# TOP_RCM_TOP_RCM register map
Vendor: Texas Instruments
Peripheral module from a debugger description file (folder AM263).
Registers are 32-bit, read-write, reset 0x0 unless marked. A register's access mark holds for its fields unless they carry their own. Offsets are as the file gives them; lines under a group give offsets from that group; [hi:lo] are bit positions; {n}, {i} and the like mark numbered series; 'fields as' and 'values as' point back to an identical list; <NAME> marks a mode.

## TOP_RCM_TOP_RCM
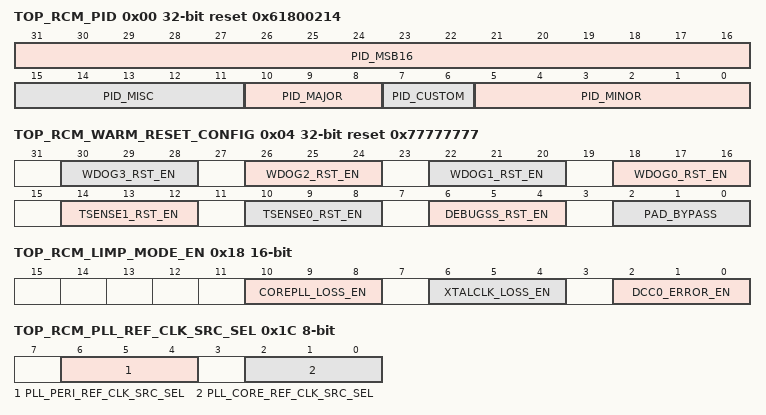
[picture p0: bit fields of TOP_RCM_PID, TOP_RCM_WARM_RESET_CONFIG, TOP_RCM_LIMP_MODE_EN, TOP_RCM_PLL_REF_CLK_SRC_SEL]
0x00 TOP_RCM_PID ro reset 0x61800214
  [31:16] PID_MSB16 — Not Defined
  [15:11] PID_MISC — Not Defined
  [10:8] PID_MAJOR — Not Defined
  [7:6] PID_CUSTOM — Not Defined
  [5:0] PID_MINOR — Not Defined
0x04 TOP_RCM_WARM_RESET_CONFIG reset 0x77777777
  [4n+18:4n+16] WDOG{n}_RST_EN (n=0..3) — Data should be loaded as multibit. Write 3'b000 to disable corresponding Watchdog control on Warm reset Write 3'b111 enable corresponding Watchdog to control Warm reset
  [14:12] TSENSE1_RST_EN — Data should be loaded as multibit. Write 3'b000 to disable temperature sensor 1 on Warm reset Write 3'b111 to enable temperature sensor 1l on Warm reset
  [10:8] TSENSE0_RST_EN — Data should be loaded as multibit. Write 3'b000 to disable temperature sensor 0 control on Warm reset Write 3'b111 to enable temperature sensor 0 control on Warm reset
  [6:4] DEBUGSS_RST_EN — Data should be loaded as multibit. Write 3'b000 to disable debugger control on Warm reset Write 3'b111 enable debugger to control Warm reset
  [2:0] PAD_BYPASS — Bypass the Warm reset from Pad InputData should be loaded as multibit. Write 3'b000 : Pad Warm Reset pin has control over warm resetWrite 3'b111 : Pad warm reset pin has no control on warm reset
0x08 TOP_RCM_WARM_RESET_REQ 8-bit reset 0x7
  [2:0] SW_RST — Data should be loaded as multibit. Write 3'b000 to assert warm reset from SWWrite 3'b111 to deassert warm reset from SW if this is the only source of warm reset
0x0C TOP_RCM_WARM_RST_CAUSE 16-bit ro reset 0x41
  [11:0] CAUSE — System Reset Cause register12'b0000_0100_0001 - POR reset12'b0000_0100_0010 - Warm reset due to MSS_WDT012'b0000_0100_0100 - Warm reset due to MSS_WDT112'b0000_0100_1000 - Warm reset due to MSS_WDT212'b0000_0101_0000 - Warm reset due to MSS_WDT312'b0000_0110_0000 - Warm reset due to TOP_RMC:WARM_RESET_REQ12'b0000_0100_0000 - External Pad reset12'b0000_1100_0000 - Warm reset due to HSM_WDT12'b0001_0100_0000 - Warm Reset due to Deugger reset12'b0010_0100_0000 - Warm Reset due to Temp Sense0 Reset12'b0100_0100_0000 - Warm Reset due to Temp Sense1 Reset
0x10 TOP_RCM_WARM_RST_CAUSE_CLR 8-bit
  [2:0] CLEAR — Write pulse bit field: Data should be loaded as multibit. System Reset Cause register Clear
0x14 TOP_RCM_RCOSC32K_CTRL 8-bit
  [2:0] STOPOSC — Stop 32KHz RCOSC. Write 3'b111 to stop clock
0x18 TOP_RCM_LIMP_MODE_EN 16-bit
  [10:8] COREPLL_LOSS_EN — Enable for core pll phase lock loss to generate Limp mode3'b000: will not generate Limp mode (multibit 000)3'b111 : will generate Limp mode (multibit 111)
  [6:4] XTALCLK_LOSS_EN — Enable for crystal_clock_loss to generate Limp mode3'b000: will not generate Limp mode (multibit 000)3'b111 : will generate Limp mode (multibit 111)
  [2:0] DCC0_ERROR_EN — Enable DCC0 Error to generate Limp mode 3'b000: DCC0 Error will not generate Limp mode (multibit 000)3'b111 : DCC0 Error will generate Limp mode (multibit 111)
0x1C TOP_RCM_PLL_REF_CLK_SRC_SEL 8-bit
  [6:4] PLL_PERI_REF_CLK_SRC_SEL — Mux selct for PERI PLL REF clockWrite 3'b111 : to select external reference clock as PLL reference clockWrite 3'b000 : to select on-die clock as PLL reference clock
  [2:0] PLL_CORE_REF_CLK_SRC_SEL — Mux selct for CORE PLL REF clockWrite 3'b111 : to select external reference clock as PLL reference clockWrite 3'b000 : to select on-die clock as PLL reference clock
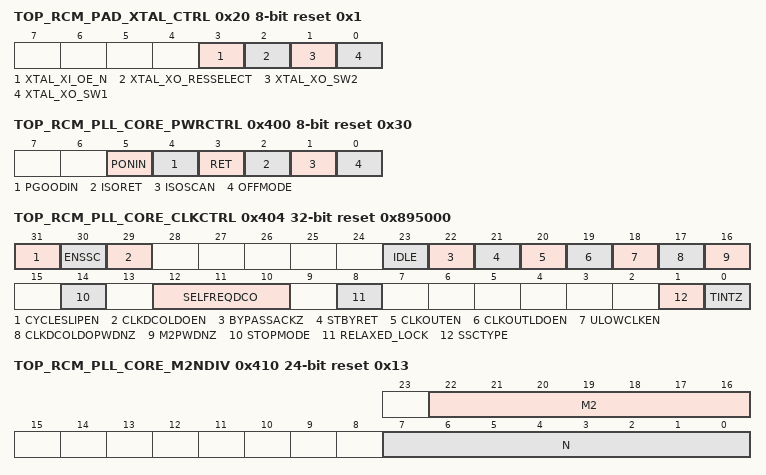
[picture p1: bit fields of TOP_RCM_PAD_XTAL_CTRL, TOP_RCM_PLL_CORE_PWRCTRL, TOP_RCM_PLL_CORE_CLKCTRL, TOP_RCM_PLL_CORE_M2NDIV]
0x20 TOP_RCM_PAD_XTAL_CTRL 8-bit reset 0x1
  [3] XTAL_XI_OE_N — When gz is low, the padxo output is enabled, padxi to padxo is a single stage inverter, and the oscillator can oscillate with an external crystal plus capacitors/resistor. When gz is high, padxo is in high impedance mode, padxi and Y are driven low, and the oscillator is disabled. With gz high, the internal bias resistor between padxi and padxo is disconnected regardless of the state of resselect.
  [2] XTAL_XO_RESSELECT — When resselect is low, an internal 1Meg Ohm resistor is connected between padxi and padxo for oscillator bias. When resselect is asserted (high), the internal resistor is disconnected. For oscillation with a crystal while resselect is high, an external resistor must be connected between padxi and padxo to provide bias.
  [1] XTAL_XO_SW2 — XTAL pad control bit frequency selection pin SW2 Based on table belowsw2 sw1 Freq of operation0 0 5 20 MHz0 1 15 35 MHz1 0 30 40 MHz1 1 40 55 MHz
  [0] XTAL_XO_SW1 — XTAL pad control bit frequency selection pin SW1 Based on table belowsw2 sw1 Freq of operation0 0 5 20 MHz0 1 15 35 MHz1 0 30 40 MHz1 1 40 55 MHz
0x24 TOP_RCM_SOP_MODE_VALUE ro
  [31:0] VAL — See below table SOP_MODE values and its corresponding mappingSOP_PAD3 SOP_PAD2 SOP_PAD1 SOP_PAD0 bootmode 0 0 0 0 QSPI Functional mode(4S) 0 0 0 1 UART Functional mode 0 0 1 0 QSPI Functional mode(1S) values from 3 to 7 is reserved for future use 1 0 0 0 THB(test) mode 1 0 0 1 ATPG mode 1 0 1 0 FLED mode (Debug SoP mode) values from B to F is reserved for future use reset value of MMR is 0 but it will latch on to the SOP mode values after reset is released. when CPU reads the MMR it will show the latched SOP mode value only
0x28 TOP_RCM_CLK_LOSS_STATUS 8-bit ro reset 0x100
  [8] RC_GOOD_BOOT — Clock status of RC clock at boot. Reset value will reflect the actual status1 --> clock present at boot0 --> clock not present at boot
  [4] RC_CLOCK_LOSS — Coarse detection clock loss status for RC clock. Reset value will reflect the actual status1 --> clock lost0 --> clock good
  [0] CRYSTAL_CLOCK_LOSS — Coarse detection clock loss status for Crystal clock. Reset value will reflect the actual status1 --> clock lost0 --> clock good
0x30 TOP_RCM_WARM_RSTTIME1 16-bit reset 0x888
  [11:0] DELAY — programing Output delay Data should be loaded as multibit. For example: if value of 0x5 should be selected then 0x555 should be configured to the register.
0x34 TOP_RCM_WARM_RSTTIME2 16-bit reset 0x888
  [11:0] DELAY — programing input Rise delay Data should be loaded as multibit. For example: if value of 0x5 should be selected then 0x555 should be configured to the register.
0x38 TOP_RCM_WARM_RSTTIME3 16-bit reset 0x111
  [11:0] DELAY — programing Input Fall delay Data should be loaded as multibit. For example: if value of 0x5 should be selected then 0x555 should be configured to the register.
0x400 TOP_RCM_PLL_CORE_PWRCTRL 8-bit reset 0x30
  [5] PONIN — ON/OFF control of the weak power switch digital. For functionalmode it should be 1
  [4] PGOODIN — ON/OFF control of the strong power switch digital. For functional mode it should be 1
  [3] RET — Save/Restore control for Retention mode. For functional mode itshould be 0
  [2] ISORET — Save/Restore control for Isolation of output pins For functional modeit should be 0
  [1] ISOSCAN — Save/Restore control for Isolation of the Scanout pins. For functionalmode it should be 0
  [0] OFFMODE — Used to switch OFF the logic on VDDA. For functional mode itshould be 0
0x404 TOP_RCM_PLL_CORE_CLKCTRL reset 0x895000
  [31] CYCLESLIPEN — FailSafe enable to trigger re-calibration in case CycleSlip occurs between REFCLK and FBCLK.
  [30] ENSSC — Controls Clock Spreading. SSC is not supported. Should be set to 0x0 to disable clock spreading.
  [29] CLKDCOLDOEN — Synchronously enables/disables CLKDCOLDO0x0 : synchronously disables CLKDCOLDO0x1 : synchronously enables CLKDCOLDO
  [23] IDLE — Sets PLL to Idle mode0x0 : When SYSRESET = 0 and TINITZ = 1 IDLE = 0 PLL will go toActive and Locked0x1 : When SYSRESET = 0 and TINITZ = 1 IDLE = 1 PLL will go toIdle Bypass low powe
  [22] BYPASSACKZ — BYPASSACKZ is a special purpose input to the module. In generalthis input is expected to be tied to static low. For the output clocks ofthe module that do not have an internal bypass mux viz.CLKDCOLDO and CLKOUTLDO, a bypass mux could beimplemented external to the module.
  [21] STBYRET — Standby retention control0x0 : prepares ADPLLLJ for relock when out of retention byremoving the gating on all internal clocks.0x1 : prepares ADPLLLJ for retention by gating all the internalclocks.
  [20] CLKOUTEN — CLKOUT enable or disable0x0 : synchronously disables CLKOUT0x1 : synchronously enables CLKOUT
  [19] CLKOUTLDOEN — Synchronously enables/disables CLKOUTLDO 0x0 : synchronously disables CLKOUTLDO 0x1 : synchronously enables CLKOUTLDO
  [18] ULOWCLKEN — Select CLKOUT source in bypass0x0: When ADPLLLJ in bypass mode, CLKOUT = CLKINP/(N2+1)0x1: When ADPLLLJ in bypass mode, CLKOUT = CLKINPULOW.
  [17] CLKDCOLDOPWDNZ — 0 Asynchronous power down for CLKDCOLDO o/p.
  [16] M2PWDNZ — M2 divider power down mode0x0: Asynchronous power down for M2 divider0x1 : M2 divider is functional
  [14] STOPMODE — When in Lossclk/Stbyret 0x0 : Limp mode 0x1 : Stopmode
  [12:10] SELFREQDCO — DCO Clock (DCOCLK = CLKINP * [M/(N+1)]) frequency rangeselector.0x0: Reserved0x2: HS2 : DCOCLK range is from 500 MHz to 1000 MHz0x3: Reserved0x4: HS1: DCOCLK range is from 1000 MHz to 2000 MHz0x5: Reserved
  [8] RELAXED_LOCK — Decides when FREQLOCK asserted0x0: FREQLOCK asserted when DC frequency error less than 1%0x1: FREQLOCK asserted when DC frequency error less than 2%
  [1] SSCTYPE
  [0] TINTZ — PLL core soft reset
0x408 TOP_RCM_PLL_CORE_TENABLE size not given
  [0] TENABLE — M, N. SD and SELFREQDCO latch (active rise edge)
0x40C TOP_RCM_PLL_CORE_TENABLEDIV size not given
  [0] TENABLEDIV — M2 and N2 latch (active rise edge)
0x410 TOP_RCM_PLL_CORE_M2NDIV 24-bit reset 0x13
  [22:16] M2 — Post-divider is REGM2
  [7:0] N — Pre-divider is REGN+1
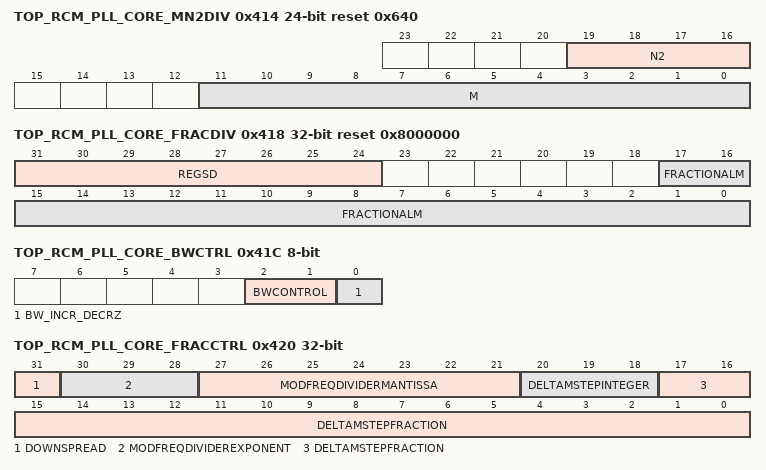
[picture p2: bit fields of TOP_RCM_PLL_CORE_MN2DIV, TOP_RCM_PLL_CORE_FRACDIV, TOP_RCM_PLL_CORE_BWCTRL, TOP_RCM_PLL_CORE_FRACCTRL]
0x414 TOP_RCM_PLL_CORE_MN2DIV 24-bit reset 0x640
  [19:16] N2 — Bypass divider is REGN2+1
  [11:0] M — Feedback Multiplier is REGM
0x418 TOP_RCM_PLL_CORE_FRACDIV reset 0x8000000
  [31:24] REGSD — Sigma-Delta DividerShould be set by s/w to provide optimum jitter performance.DPLL_SD_DIV = CEILING ([DPLL_MULT/(DPLL_DIV+1)] * CLKINP/ 250), where CLKINP is the input clock of the DPLL in MHz
  [17:0] FRACTIONALM — Fractional part of the M divider.
0x41C TOP_RCM_PLL_CORE_BWCTRL 8-bit
  [2:1] BWCONTROL — Change Loop Bandwidth
  [0] BW_INCR_DECRZ — Direction of Loop Bandwidth0x0 : decrease BW0x1 : increase BW
0x420 TOP_RCM_PLL_CORE_FRACCTRL
  [31] DOWNSPREAD — Controls frequency spread0x0 : enables both side frequency spread about the programmed frequency.0x1 : enables low frequency spread only
  [30:28] MODFREQDIVIDEREXPONENT — Exponent of the REFCLK divider to define the modulation frequency.
  [27:21] MODFREQDIVIDERMANTISSA — Mantissa of the REFCLK divider to define the modulation frequency
  [20:18] DELTAMSTEPINTEGER — Integer part of Frequency Spread control
  [17:0] DELTAMSTEPFRACTION — The fraction part of Frequency Spread control
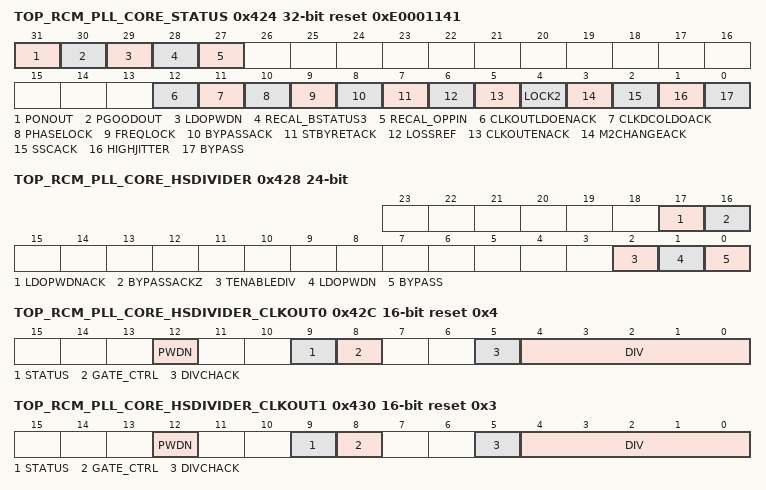
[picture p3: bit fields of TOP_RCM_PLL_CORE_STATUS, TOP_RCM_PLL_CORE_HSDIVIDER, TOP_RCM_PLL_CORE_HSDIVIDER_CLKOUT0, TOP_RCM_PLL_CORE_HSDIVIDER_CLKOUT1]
0x424 TOP_RCM_PLL_CORE_STATUS ro reset 0xE0001141
  [31] PONOUT — Status of the weak power-switch0x0 : indicates the/OFF status of the weak power-switch in digital toSOC.0x1 : ndicates the ON status of the weak power-switch in digital toSOC.
  [30] PGOODOUT — Status of the strong power-switch0x0 : indicates the/OFF status of the strong power-switch in digital toSOC.0x1 : ndicates the ON status of the strong power-switch in digital toSOC.
  [29] LDOPWDN — 1 indicates ADPLLLJ internal LDO is power down. VDDLDOOUT willbe un-defined in this condition
  [28] RECAL_BSTATUS3 — Recalibration status flag. 1 ADPLLLJ requires recalibration
  [27] RECAL_OPPIN — Recalibration status flag. 1 ADPLLLJ requires recalibration
  [12] CLKOUTLDOENACK — Indicates the enable/disable condition of CLKOUTLDOEN0x0 = CLKOUTLDO gating completed0x1 = CLKOUTLDO enabling completed
  [11] CLKDCOLDOACK — Indicates the enable/disable condition of CLKDCOLDOEN0x0 = CLKDCOLDO gating completed0x1 = CLKDCOLOD enabling completed
  [10] PHASELOCK — Status on PHASELOCK output pin
  [9] FREQLOCK — Status on FREQLOCK output pin
  [8] BYPASSACK — Status of BYPASSACK output pin
  [7] STBYRETACK — Standby and retention status0x0: indicates to SOC that all internal clocks in ADPLLLJ are activeand it is starting the relock process.0x1: indicates to SOC that all internal clocks in ADPLLLJ are gatedand it is ready for retention.
  [6] LOSSREF — Reference input loss
  [5] CLKOUTENACK — Indicates the enable/disable condition of CLKOUTEN0x0 = CLKOUT gating completed0x1 = CLKOUT enabling completed
  [4] LOCK2 — ADPLL internal loop lock status
  [3] M2CHANGEACK — Acknowledge for change to M2 divider. Toggles from 1-0 or 0-1(depending on current value) once CLKOUT frequency change hascompleted.
  [2] SSCACK — Spread Spectrum status0x0 : Spread-spectrum Clocking is disabled on output clocks0x1 : Spread-spectrum Clocking is enabled on output clocks
  [1] HIGHJITTER — 1 indicates jitter. After PHASELOCK is asserted high, theHIGHJITTER flag is asserted high if phase error between REFCLKand FBCLK greater than 24%.
  [0] BYPASS — Bypass status signal. 1 CLKOUT in bypass
0x428 TOP_RCM_PLL_CORE_HSDIVIDER 24-bit access per field
  [17] LDOPWDNACK ro — LDO Power Down Ack
  [16] BYPASSACKZ ro — HSDIVIDER Bypass Ack
  [2] TENABLEDIV rw
  [1] LDOPWDN rw — LDO Power Down
  [0] BYPASS rw — HSDIVIDER Bypass
0x42C TOP_RCM_PLL_CORE_HSDIVIDER_CLKOUT0 16-bit access per field reset 0x4
  [12] PWDN rw — Power down for HSDIVIDER M4 divider and hence CLKOUT0 output0h (R/W) = CLKOUT0 divider active1h (R/W) = CLKOUT0 divider is powered down
  [9] STATUS ro — HSDIVIDER CLKOUT0 status0h (R) = The clock output is gated1h (R) = The clock output is enabled
  [8] GATE_CTRL rw — Control gating of HSDIVIDER CLKOUT00h (R/W) = Automatically gate this clock when there is nodependency for it1h (R/W) = Force this clock to stay enabled even if there is norequest
  [5] DIVCHACK ro — Toggle on this status bit after changing HSDIVIDER_CLKOUT0_DIVindicates that the change in divider value has taken effect
  [4:0] DIV rw — DPLL post-divider factor, M4, for internal clock generation.Divide values from 1 to 31.0h (R/W) = Reserved
0x430 TOP_RCM_PLL_CORE_HSDIVIDER_CLKOUT1 16-bit access per field reset 0x3
  [12] PWDN rw — Power down for HSDIVIDER M5 divider and hence CLKOUT1 output0h (R/W) = CLKOUT1 divider active1h (R/W) = CLKOUT1 divider is powered down
  [9] STATUS ro — HSDIVIDER CLKOUT1 status0h (R) = The clock output is gated1h (R) = The clock output is enabled
  [8] GATE_CTRL rw — Control gating of HSDIVIDER CLKOUT10h (R/W) = Automatically gate this clock when there is nodependency for it1h (R/W) = Force this clock to stay enabled even if there is norequest
  [5] DIVCHACK ro — Toggle on this status bit after changing HSDIVIDER_CLKOUT1_DIVindicates that the change in divider value has taken effect
  [4:0] DIV rw — DPLL post-divider factor, M5, for internal clock generation.Divide values from 1 to 31.0h (R/W) = Reserved
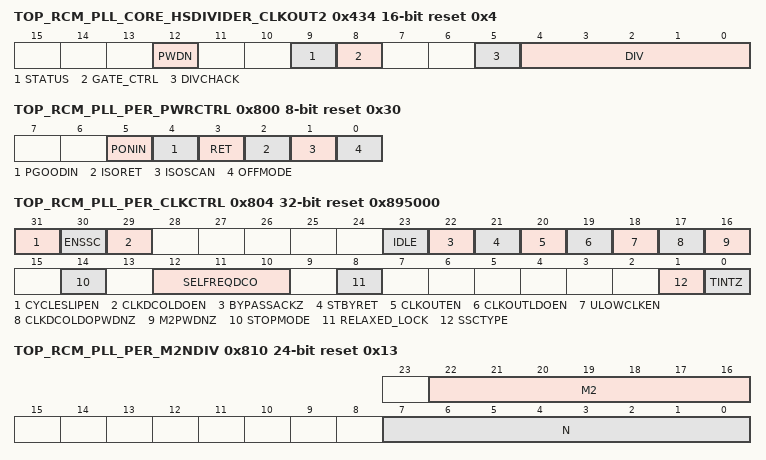
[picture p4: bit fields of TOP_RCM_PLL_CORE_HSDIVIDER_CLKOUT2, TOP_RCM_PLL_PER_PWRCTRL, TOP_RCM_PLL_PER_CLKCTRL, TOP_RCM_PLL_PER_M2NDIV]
0x434 TOP_RCM_PLL_CORE_HSDIVIDER_CLKOUT2 16-bit access per field reset 0x4
  [12] PWDN rw — Power down for HSDIVIDER M6 divider and hence CLKOUT2 output0h (R/W) = CLKOUT2 divider active1h (R/W) = CLKOUT2 divider is powered down
  [9] STATUS ro — HSDIVIDER CLKOUT2 status0h (R) = The clock output is gated1h (R) = The clock output is enabled
  [8] GATE_CTRL rw — Control gating of HSDIVIDER CLKOUT20h (R/W) = Automatically gate this clock when there is nodependency for it1h (R/W) = Force this clock to stay enabled even if there is norequest
  [5] DIVCHACK ro — Toggle on this status bit after changing HSDIVIDER_CLKOUT2_DIVindicates that the change in divider value has taken effect
  [4:0] DIV rw — DPLL post-divider factor, M6, for internal clock generation.Divide values from 1 to 31.0h (R/W) = Reserved
0x43C TOP_RCM_PLL_CORE_RSTCTRL 8-bit
  [2:0] ASSERT — SW Reset override for the PLLWrite 3'b111 : Override is enabled and Reset is asserted
0x440 TOP_RCM_PLL_CORE_HSDIVIDER_RSTCTRL 8-bit
  [2:0] ASSERT — SW Reset override for the HSDIVIDERWrite 3'b111 : Override is enabled and Reset is asserted
0x500 TOP_RCM_R5SS_CLK_SRC_SEL 16-bit
  [11:0] CLKSRCSEL — Select line for selecting source clock for MSS Coretex R5 and System bus Clock.Data should be loaded as multibit. For example: if Clock source 0x5 should be selected then 0x555 should be configured to the register.Refer to AM602 clock spec for source clock reference
0x504 TOP_RCM_R5SS_CLK_STATUS 8-bit ro reset 0x1
  [7:0] CLKINUSE — Status shows the source clock slected for Root clock for CortexR5 and Sysclk
0x510 TOP_RCM_R5SS0_CLK_DIV_SEL 8-bit
  [2:0] CLKDIVSEL — writing 3'b000 Sets R5 clock = R5SS Root clockWriting 3'b111 Sets R5 Clock = SYSCLK
0x514 TOP_RCM_R5SS1_CLK_DIV_SEL 8-bit
  fields as TOP_RCM_R5SS0_CLK_DIV_SEL
0x518 TOP_RCM_R5SS0_CLK_GATE 8-bit
  [2:0] GATED — Only for debug- Functionality not guaranteed Clock gating config for MSS Coretex R5.Data should be loaded as multibit. Write 3'b000 : Clock is ungated (multibit 000)Write 3'b111 : Clock is gated (multibit 111)
0x51C TOP_RCM_R5SS1_CLK_GATE 8-bit
  fields as TOP_RCM_R5SS0_CLK_GATE
0x520 TOP_RCM_SYS_CLK_DIV_VAL 16-bit
  [11:0] CLKDIV — Divider value for System Clock selected clock.Data should be loaded as multibit. For example: if divider value of 0x5 should be selected then 0x555 should be configured to the register.
0x524 TOP_RCM_SYS_CLK_GATE 8-bit
  [2:0] GATED — Only for debug- Functionality not guaranteed Clock gating config for System ClockData should be loaded as multibit. Write 3'b000 : Clock is ungated (multibit 000)Write 3'b111 : Clock is gated (multibit 111)
0x528 TOP_RCM_SYS_CLK_STATUS 16-bit ro
  [15:8] CURRDIVIDER — Status shows the current divider value choosen for Sys Clock
0x800 TOP_RCM_PLL_PER_PWRCTRL 8-bit reset 0x30
  fields as TOP_RCM_PLL_CORE_PWRCTRL
0x804 TOP_RCM_PLL_PER_CLKCTRL reset 0x895000
  fields as TOP_RCM_PLL_CORE_CLKCTRL
0x808 TOP_RCM_PLL_PER_TENABLE size not given
  [0] TENABLE — M, N. SD and SELFREQDCO latch (active rise edge)
0x80C TOP_RCM_PLL_PER_TENABLEDIV size not given
  [0] TENABLEDIV — M2 and N2 latch (active rise edge)
0x810 TOP_RCM_PLL_PER_M2NDIV 24-bit reset 0x13
  [22:16] M2 — Post-divider is REGM2
  [7:0] N — Pre-divider is REGN+1
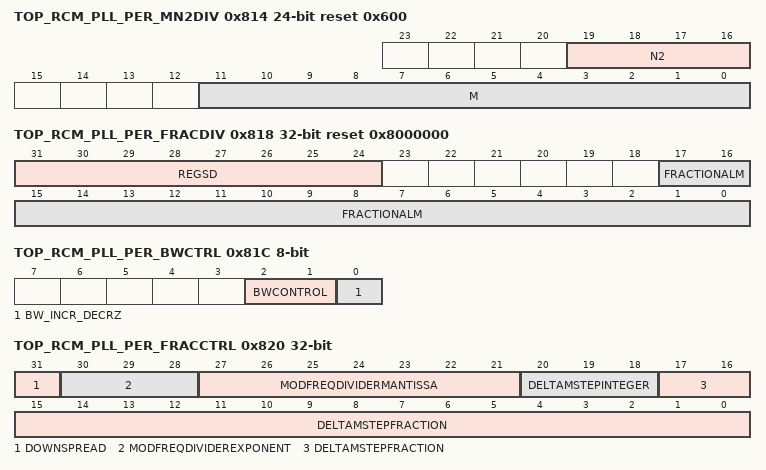
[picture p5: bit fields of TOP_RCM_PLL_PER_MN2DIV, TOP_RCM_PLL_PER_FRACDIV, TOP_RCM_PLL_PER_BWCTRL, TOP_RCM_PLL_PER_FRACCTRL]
0x814 TOP_RCM_PLL_PER_MN2DIV 24-bit reset 0x600
  fields as TOP_RCM_PLL_CORE_MN2DIV
0x818 TOP_RCM_PLL_PER_FRACDIV reset 0x8000000
  fields as TOP_RCM_PLL_CORE_FRACDIV
0x81C TOP_RCM_PLL_PER_BWCTRL 8-bit
  fields as TOP_RCM_PLL_CORE_BWCTRL
0x820 TOP_RCM_PLL_PER_FRACCTRL
  fields as TOP_RCM_PLL_CORE_FRACCTRL
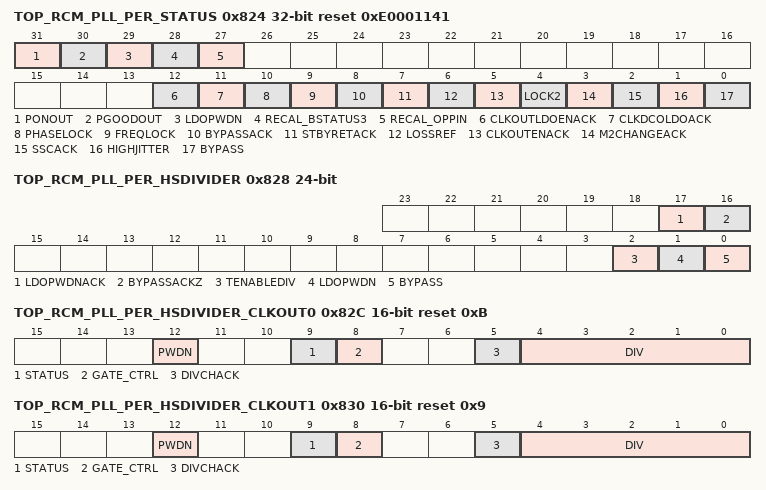
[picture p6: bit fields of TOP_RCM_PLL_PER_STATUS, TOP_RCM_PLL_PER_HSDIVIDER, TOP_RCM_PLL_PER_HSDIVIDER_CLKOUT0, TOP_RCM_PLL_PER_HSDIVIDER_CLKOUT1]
0x824 TOP_RCM_PLL_PER_STATUS ro reset 0xE0001141
  [31] PONOUT — Status of the weak power-switch0x0 : indicates the/OFF status of the weak power-switch in digital toSOC.0x1 : ndicates the ON status of the weak power-switch in digital toSOC.
  [30] PGOODOUT — Status of the strong power-switch0x0 : indicates the/OFF status of the strong power-switch in digital toSOC.0x1 : ndicates the ON status of the strong power-switch in digital toSOC.
  [29] LDOPWDN — 1 indicates ADPLLLJ internal LDO is power down. VDDLDOOUT willbe un-defined in this condition
  [28] RECAL_BSTATUS3 — Recalibration status flag. 1 ADPLLLJ requires recalibration
  [27] RECAL_OPPIN — Recalibration status flag. 1 ADPLLLJ requires recalibration
  [12] CLKOUTLDOENACK — Indicates the enable/disable condition of CLKOUTLDOEN0x0 = CLKOUTLDO gating completed0x1 = CLKOUTLDO enabling completed
  [11] CLKDCOLDOACK — Indicates the enable/disable condition of CLKDCOLDOEN0x0 = CLKDCOLDO gating completed0x1 = CLKDCOLDO enabling completed
  [10] PHASELOCK — Status on PHASELOCK output pin
  [9] FREQLOCK — Status on FREQLOCK output pin
  [8] BYPASSACK — Status of BYPASSACK output pin
  [7] STBYRETACK — Standby and retention status0x0: indicates to SOC that all internal clocks in ADPLLLJ are activeand it is starting the relock process.0x1: indicates to SOC that all internal clocks in ADPLLLJ are gatedand it is ready for retention.
  [6] LOSSREF — Reference input loss
  [5] CLKOUTENACK — Indicates the enable/disable condition of CLKOUTEN0x0 = CLKOUT gating completed0x1 = CLKOUT enabling completed
  [4] LOCK2 — ADPLL internal loop lock status
  [3] M2CHANGEACK — Acknowledge for change to M2 divider. Toggles from 1-0 or 0-1(depending on current value) once CLKOUT frequency change hascompleted.
  [2] SSCACK — Spread Spectrum status0x0 : Spread-spectrum Clocking is disabled on output clocks0x1 : Spread-spectrum Clocking is enabled on output clocks
  [1] HIGHJITTER — 1 indicates jitter. After PHASELOCK is asserted high, theHIGHJITTER flag is asserted high if phase error between REFCLKand FBCLK greater than 24%.
  [0] BYPASS — Bypass status signal. 1 CLKOUT in bypass
0x828 TOP_RCM_PLL_PER_HSDIVIDER 24-bit access per field
  fields as TOP_RCM_PLL_CORE_HSDIVIDER
0x82C TOP_RCM_PLL_PER_HSDIVIDER_CLKOUT0 16-bit access per field reset 0xB
  fields as TOP_RCM_PLL_CORE_HSDIVIDER_CLKOUT0
0x830 TOP_RCM_PLL_PER_HSDIVIDER_CLKOUT1 16-bit access per field reset 0x9
  fields as TOP_RCM_PLL_CORE_HSDIVIDER_CLKOUT1
0x83C TOP_RCM_PLL_PER_RSTCTRL 8-bit
  fields as TOP_RCM_PLL_CORE_RSTCTRL
0x840 TOP_RCM_PLL_PER_HSDIVIDER_RSTCTRL 8-bit
  fields as TOP_RCM_PLL_CORE_HSDIVIDER_RSTCTRL
0xC00 TOP_RCM_CLKOUT0_CLK_SRC_SEL 16-bit
  [11:0] CLKSRCSEL — Select line for selecting source clock for MSS CLKOUT .Data should be loaded as multibit. For example: if Clock source 0x5 should be selected then 0x555 should be configured to the register.Refer to AM602 clock spec for source clock reference
0xC04 TOP_RCM_CLKOUT1_CLK_SRC_SEL 16-bit
  fields as TOP_RCM_CLKOUT0_CLK_SRC_SEL
0xC08 TOP_RCM_CLKOUT0_DIV_VAL 16-bit
  [11:0] CLKDIV — Divider value for CLKOUT selected clock.Data should be loaded as multibit. For example: if divider value of 0x5 should be selected then 0x555 should be configured to the register.
0xC0C TOP_RCM_CLKOUT1_DIV_VAL 16-bit
  fields as TOP_RCM_CLKOUT0_DIV_VAL
0xC10 TOP_RCM_CLKOUT0_CLK_GATE 8-bit
  [2:0] GATED — Only for debug- Functionality not guaranteed Clock gating config for MSS CLKOUTData should be loaded as multibit. Write 3'b000 : Clock is ungated (multibit 000)Write 3'b111 : Clock is gated (multibit 111)
0xC14 TOP_RCM_CLKOUT1_CLK_GATE 8-bit
  fields as TOP_RCM_CLKOUT0_CLK_GATE
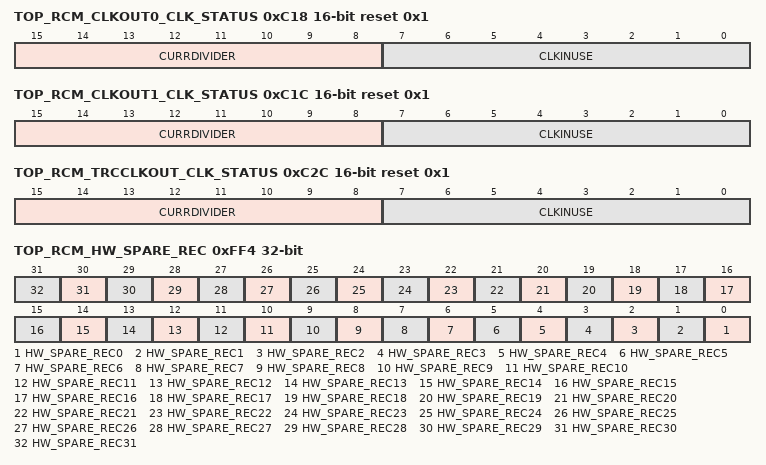
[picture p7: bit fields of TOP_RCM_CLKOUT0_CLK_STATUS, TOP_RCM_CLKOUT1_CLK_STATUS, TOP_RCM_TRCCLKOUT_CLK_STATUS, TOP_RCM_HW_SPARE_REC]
0xC18 TOP_RCM_CLKOUT0_CLK_STATUS 16-bit ro reset 0x1
  [15:8] CURRDIVIDER — Status shows the current divider value choosen for CLKOUT Clock
  [7:0] CLKINUSE — Status shows the source clock slected for CLKOUT Clock
0xC1C TOP_RCM_CLKOUT1_CLK_STATUS 16-bit ro reset 0x1
  fields as TOP_RCM_CLKOUT0_CLK_STATUS
0xC20 TOP_RCM_TRCCLKOUT_CLK_SRC_SEL 16-bit
  [11:0] CLKSRCSEL — Select line for selecting source clock for TRC ClkoutData should be loaded as multibit. For example: if Clock source 0x5 should be selected then 0x555 should be configured to the register.Refer to AM602 clock spec for source clock reference
0xC24 TOP_RCM_TRCCLKOUT_DIV_VAL 16-bit
  [11:0] CLKDIV — Divider value for TRC Clkout selected clock.Data should be loaded as multibit. For example: if divider value of 0x5 should be selected then 0x555 should be configured to the register.
0xC28 TOP_RCM_TRCCLKOUT_CLK_GATE 8-bit
  [2:0] GATED — Clock gatring config for TRC ClkoutData should be loaded as multibit. Write 3'b000 : Clock is ungated (multibit 000)Write 3'b111 : Clock is gated (multibit 111)
0xC2C TOP_RCM_TRCCLKOUT_CLK_STATUS 16-bit ro reset 0x1
  [15:8] CURRDIVIDER — Status shows the current divider value choosen for PMIC Clkout Clock
  [7:0] CLKINUSE — Status shows the source clock slected for PMIC Clkout Clock
0xD00 TOP_RCM_DFT_DMLED_EXEC
  [31:0] VAL — SW mapping for DMLED ExecutionBit 0 : HSM CM4 Execution Bit 1 : HWA CM4 Execution Bit 2 : MSS CR5undefined Execution
0xD04 TOP_RCM_DFT_DMLED_STATUS
  [31:0] VAL — SW mapping for DMLED StatusBit 0 : HSM CM4 Status Bit 1 : HWA CM4 Status Bit 2 : MSS CR5undefined Status
{0xE00+4i} TOP_RCM_HW_REG{i} (i=0..3)
  [31:0] HWREG — HW Reserved regiser. Reserved for HW RnD
{0xFD0+4i} TOP_RCM_HW_SPARE_RW{i} (i=0..3)
  [31:0] HW_SPARE_RW{i} — Reserved for HW R&D
{0xFE0+4i} TOP_RCM_HW_SPARE_RO{i} ro (i=0..3)
  [31:0] HW_SPARE_RO{i} — Reserved for HW R&D
0xFF0 TOP_RCM_HW_SPARE_WPH
  [31:0] HW_SPARE_WPH — Reserved for HW R&D
0xFF4 TOP_RCM_HW_SPARE_REC
  [n] HW_SPARE_REC{n} (n=0..31) — Reserved for HW R&D
0x1008 TOP_RCM_LOCK0_KICK0
  [31:0] LOCK0_KICK0 — - KICK0 component
0x100C TOP_RCM_LOCK0_KICK1
  [31:0] LOCK0_KICK1 — - KICK1 component
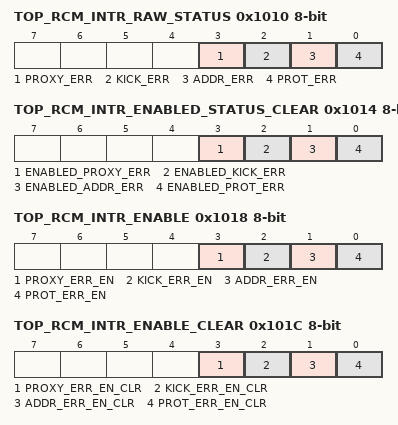
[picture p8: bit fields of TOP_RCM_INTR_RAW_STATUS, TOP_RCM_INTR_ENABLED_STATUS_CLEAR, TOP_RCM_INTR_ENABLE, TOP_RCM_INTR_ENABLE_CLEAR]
0x1010 TOP_RCM_INTR_RAW_STATUS 8-bit
  [3] PROXY_ERR — Proxy0 access violation error. Raw status is read. Write a 1 to set the status. Writing a 0 has no effect.
  [2] KICK_ERR — Kick access violation error. Raw status is read. Write a 1 to set the status. Writing a 0 has no effect.
  [1] ADDR_ERR — Addressing violation error. Raw status is read. Write a 1 to set the status. Writing a 0 has no effect.
  [0] PROT_ERR — Protection violation error. Raw status is read. Write a 1 to set the status. Writing a 0 has no effect.
0x1014 TOP_RCM_INTR_ENABLED_STATUS_CLEAR 8-bit
  [3] ENABLED_PROXY_ERR — Proxy0 access violation error. Enabled status is read. Write a 1 to clear the status. Writing a 0 has no effect.
  [2] ENABLED_KICK_ERR — Kick access violation error. Enabled status is read. Write a 1 to clear the status. Writing a 0 has no effect.
  [1] ENABLED_ADDR_ERR — Addressing violation error. Enabled status is read. Write a 1 to clear the status. Writing a 0 has no effect.
  [0] ENABLED_PROT_ERR — Protection violation error. Enabled status is read. Write a 1 to clear the status. Writing a 0 has no effect.
0x1018 TOP_RCM_INTR_ENABLE 8-bit
  [3] PROXY_ERR_EN — Proxy0 access violation error enable. Write a 1 to set the enable. Writing a 0 has no effect.
  [2] KICK_ERR_EN — Kick access violation error enable. Write a 1 to set the enable. Writing a 0 has no effect.
  [1] ADDR_ERR_EN — Addressing violation error enable. Write a 1 to set the enable. Writing a 0 has no effect.
  [0] PROT_ERR_EN — Protection violation error enable. Write a 1 to set the enable. Writing a 0 has no effect.
0x101C TOP_RCM_INTR_ENABLE_CLEAR 8-bit
  [3] PROXY_ERR_EN_CLR — Proxy0 access violation error enable clear. Write a 1 to clear the enable. Writing a 0 has no effect.
  [2] KICK_ERR_EN_CLR — Kick access violation error enable clear. Write a 1 to clear the enable. Writing a 0 has no effect.
  [1] ADDR_ERR_EN_CLR — Addressing violation error enable clear. Write a 1 to clear the enable. Writing a 0 has no effect.
  [0] PROT_ERR_EN_CLR — Protection violation error enable clear. Write a 1 to clear the enable. Writing a 0 has no effect.
0x1020 TOP_RCM_EOI 8-bit
  [7:0] EOI_VECTOR — EOI vector value. Write this with interrupt distribution value in the chip.
0x1024 TOP_RCM_FAULT_ADDRESS ro
  [31:0] FAULT_ADDR — Fault Address.
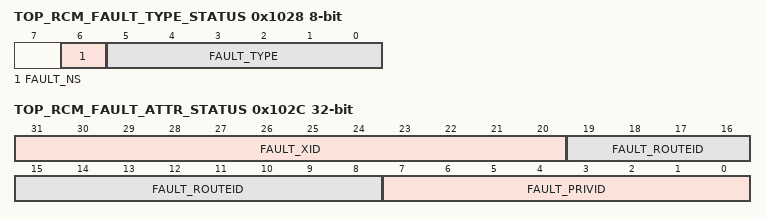
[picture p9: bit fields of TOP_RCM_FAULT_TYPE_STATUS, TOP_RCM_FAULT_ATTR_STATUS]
0x1028 TOP_RCM_FAULT_TYPE_STATUS 8-bit ro
  [6] FAULT_NS — Non-secure access.
  [5:0] FAULT_TYPE — Fault Type 10_0000 = Supervisor read fault - priv = 1 dir = 1 dtype != 1 01_0000 = Supervisor write fault - priv = 1 dir = 0 00_1000 = Supervisor execute fault - priv = 1 dir = 1 dtype = 1 00_0100 = User read fault - priv = 0 dir = 1 dtype = 1 00_0010 = User write fault - priv = 0 dir = 0 00_0001 = User execute fault - priv = 0 dir = 1 dtype = 1 00_0000 = No fault
0x102C TOP_RCM_FAULT_ATTR_STATUS ro
  [31:20] FAULT_XID — XID.
  [19:8] FAULT_ROUTEID — Route ID.
  [7:0] FAULT_PRIVID — Privilege ID.
0x1030 TOP_RCM_FAULT_CLEAR size not given wo
  [0] FAULT_CLR — Fault clear. Writing a 1 clears the current fault. Writing a 0 has no effect.
